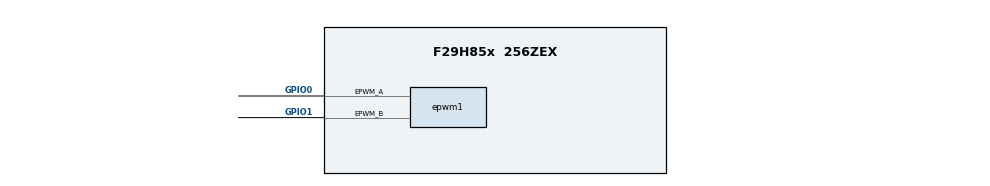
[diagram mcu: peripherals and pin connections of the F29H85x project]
/**
 * @cliArgs --device "F29H85x" --package "256ZEX" --part "F29H85x_256ZEX" --context "CPU1" --product "MCU_SDK_F29H85x@1.02.02.00"
 * @versions {"tool":"1.25.0+4237"}
 */

    
const divider15       = system.clockTree["PLL_REFDIV"];
divider15.divideValue = 1;

const multiplier1         = system.clockTree["PLL_IMULT"];
multiplier1.multiplyValue = 40;

const mux7       = system.clockTree["OSCCLKSRCSEL"];
mux7.inputSelect = "INTOSC2";

/**
 * Import the modules used in this configuration.
 */

const epwm             = scripting.addModule("/driverlib/epwm.js", {}, false);
const epwm1            = epwm.addInstance();
const eqep             = scripting.addModule("/driverlib/eqep.js", {}, false);
const eqep1            = eqep.addInstance();
const inputxbar_input  = scripting.addModule("/driverlib/inputxbar_input.js", {}, false);
const inputxbar_input1 = inputxbar_input.addInstance();
const inputxbar_input2 = inputxbar_input.addInstance();
const inputxbar_input3 = inputxbar_input.addInstance();

/**
 * Write custom configuration values to the imported modules.
 */
epwm1.$name                                                      = "myEPWM1";
epwm1.epwmTimebase_counterMode                                   = "EPWM_COUNTER_MODE_UP_DOWN";
epwm1.epwmActionQualifier_EPWM_AQ_OUTPUT_A_ON_TIMEBASE_UP_CMPA   = "EPWM_AQ_OUTPUT_HIGH";
epwm1.epwmActionQualifier_EPWM_AQ_OUTPUT_A_ON_TIMEBASE_DOWN_CMPA = "EPWM_AQ_OUTPUT_LOW";
epwm1.epwmDeadband_polarityFED                                   = "EPWM_DB_POLARITY_ACTIVE_LOW";
epwm1.epwmDeadband_enableRED                                     = true;
epwm1.epwmDeadband_enableFED                                     = true;
epwm1.epwmCounterCompare_enableShadowLoadModeCMPA                = false;
epwm1.epwmCounterCompare_enableShadowLoadModeCMPB                = false;
epwm1.epwmTimebase_hsClockDiv                                    = "EPWM_HSCLOCK_DIVIDER_1";
epwm1.epwmTimebase_periodLoadMode                                = "EPWM_PERIOD_DIRECT_LOAD";
epwm1.epwmTimebase_period                                        = 10000;
epwm1.epwmCounterCompare_cmpA                                    = 5000;
epwm1.epwm.$assign                                               = "EPWM1";
epwm1.epwm.epwm_aPin.$assign                                     = "GPIO0";
epwm1.epwm.epwm_bPin.$assign                                     = "GPIO1";
epwm1.periphClock.$name                                          = "driverlib_perClock1";
epwm1.periphConfig.$name                                         = "driverlib_perConfig1";

eqep1.$name                = "myEQEP0";
eqep1.eqepOperationMode    = "EQEP_CONFIG_UP_COUNT";
eqep1.emulationMode        = "EQEP_EMULATIONMODE_RUNFREE";
eqep1.positionCounterMax   = 4294967295;
eqep1.enableUnitTimer      = true;
eqep1.unitTimerPeriod      = 2000000;
eqep1.latchPositionCounter = "EQEP_LATCH_UNIT_TIME_OUT";
eqep1.registerInterrupts   = true;
eqep1.swPositionInit       = true;
eqep1.enableModule         = true;
eqep1.interruptSources     = ["EQEP_INT_UNIT_TIME_OUT"];
eqep1.enableInterrupt      = true;
eqep1.periphClock.$name    = "driverlib_perClock0";
eqep1.periphConfig.$name   = "driverlib_perConfig0";

inputxbar_input1.$name          = "myINPUTXBARINPUT0";
inputxbar_input1.inputxbarInput = "XBAR_INPUT33";
inputxbar_input1.inputxbarGpio  = "GPIO0";

inputxbar_input2.$name          = "myINPUTXBARINPUT1";
inputxbar_input2.inputxbarInput = "XBAR_INPUT34";
inputxbar_input2.inputxbarGpio  = "GPIO1";

inputxbar_input3.$name          = "myINPUTXBARINPUT2";
inputxbar_input3.inputxbarInput = "XBAR_INPUT35";
